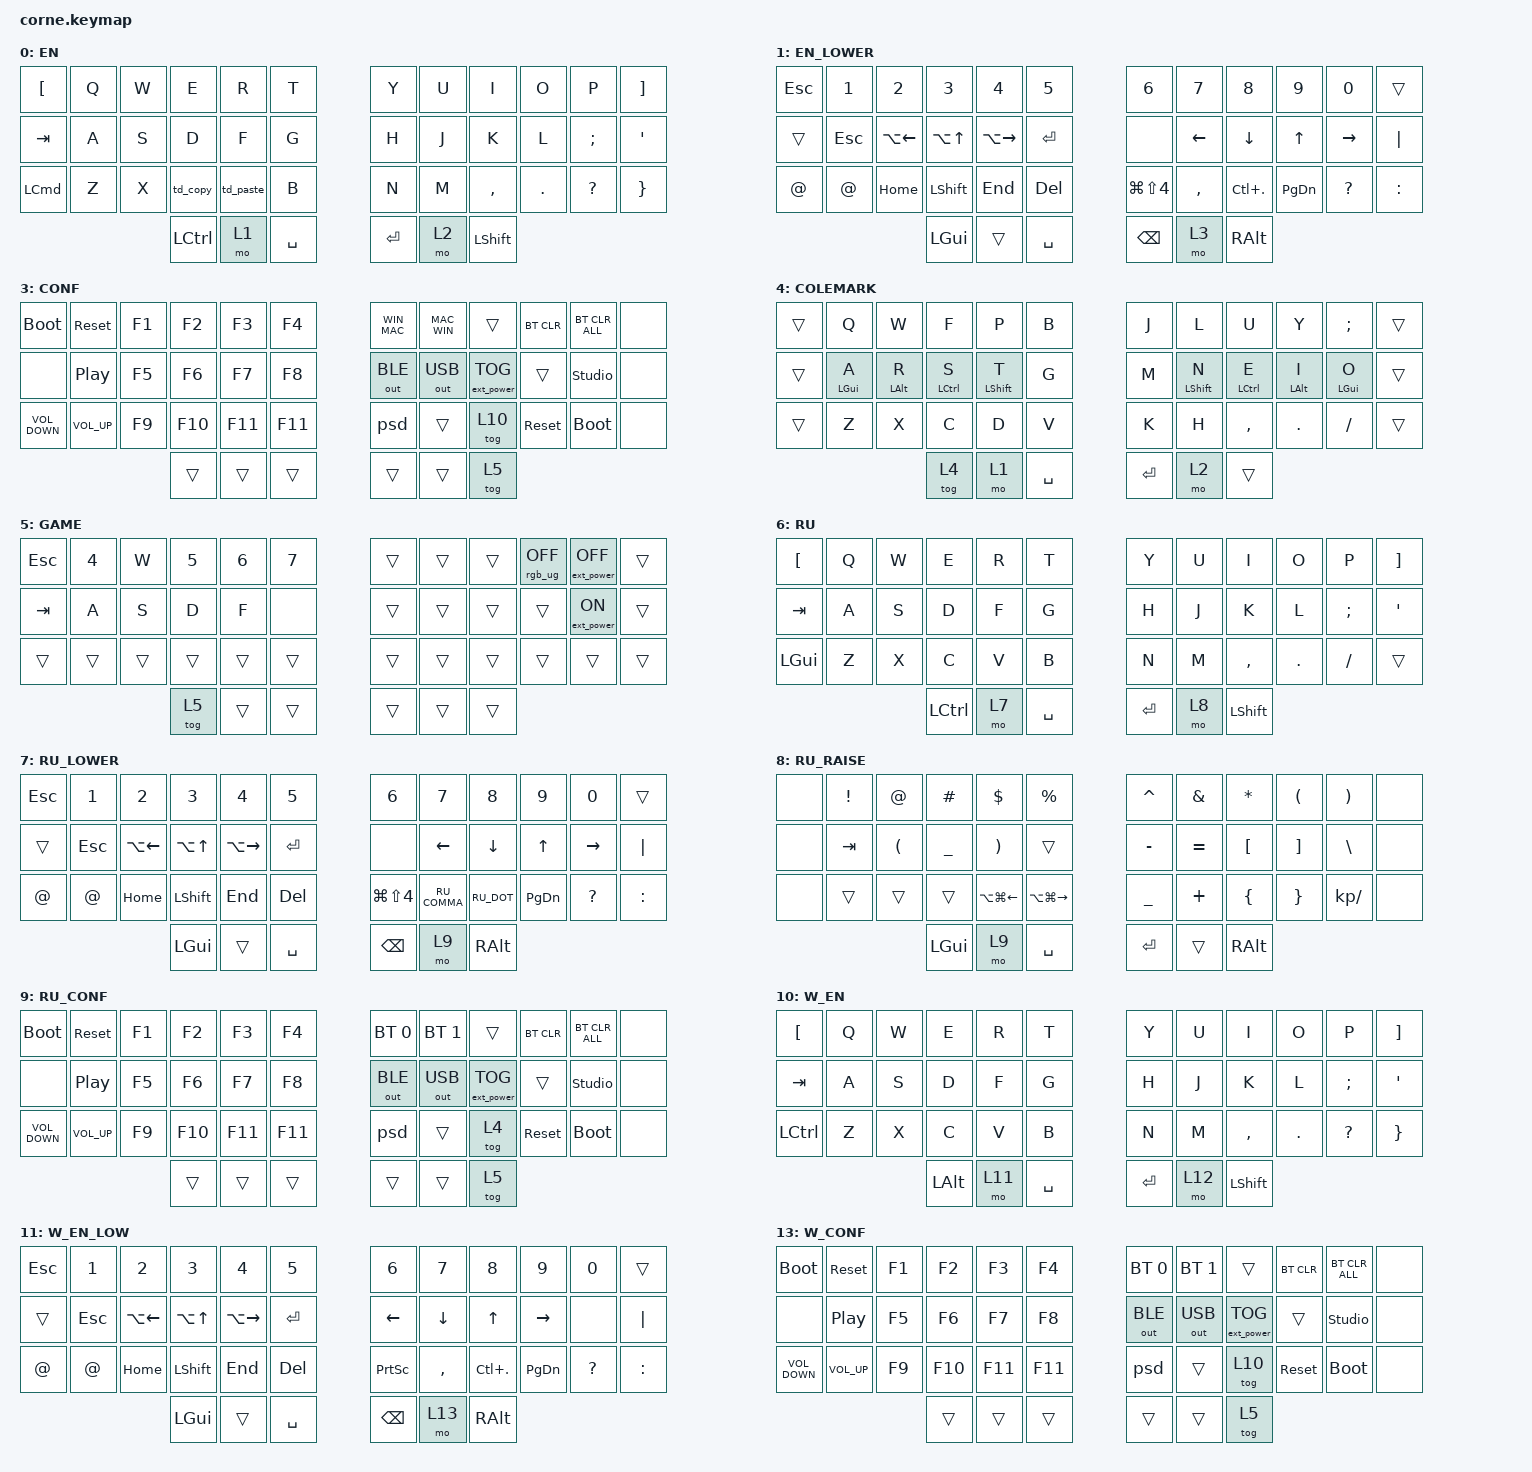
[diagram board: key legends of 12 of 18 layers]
/*
 * Copyright (c) 2020 The ZMK Contributors
 *
 * SPDX-License-Identifier: MIT
 */

#include <behaviors.dtsi>
#include <dt-bindings/zmk/bt.h>
#include <dt-bindings/zmk/ext_power.h>
#include <dt-bindings/zmk/keys.h>
#include <dt-bindings/zmk/outputs.h>
#include <dt-bindings/zmk/rgb.h>
#include "keys_ru.h"

&mt {
    tapping-term-ms = <200>;
    quick-tap-ms = <200>;
    require-prior-idle-ms = <125>;
    flavor = "tap-preferred";
};

// Переопределяем параметры дисплея ST7789
&st7789 {
    width = <240>;      // новая ширина (было 240, оставляем или меняем)
    height = <284>;     // меняем высоту, например, на 321 пикселей
    x-offset = <0>;     // смещение по X (было 0)
    y-offset = <0>;    // новое вертикальное смещение (было 20)
};

/ {
    macros {
        psd: new_macro {
            compatible = "zmk,behavior-macro";
            #binding-cells = <0>;
            bindings = <&kp LS(E) &kp C &kp N &kp F &kp N &kp Y &kp T &kp R &kp N5 &kp LS(A) &kp B &kp D &kp F &kp N5 &kp D &kp B &kp C &kp N1 &kp EXCL &kp EXCL &kp EXCL>;
            label = "NEW_MACRO";
        };

        to_ru: to_ru {
            compatible = "zmk,behavior-macro";
            #binding-cells = <0>;
            bindings = <&kp LS(LC(N2))>;
            label = "TO_RU";
        };

        to_en: to_en {
            compatible = "zmk,behavior-macro";
            #binding-cells = <0>;
            bindings = <&kp LS(LC(N1))>;
            label = "TO_EN";
        };

        layer_en: layer_en {
            compatible = "zmk,behavior-macro";
            #binding-cells = <0>;
            bindings = <&to 0 &to_en>;
            label = "LAYER_EN";
        };

        layer_ru: layer_ru {
            compatible = "zmk,behavior-macro";
            #binding-cells = <0>;
            bindings = <&to 6 &to_ru>;
            label = "LAYER_RU";
        };

        en: en {
            compatible = "zmk,behavior-macro-one-param";
            #binding-cells = <1>;
            bindings =
                <&to_en &macro_param_1to1 &kp MACRO_PLACEHOLDER>,
                <&macro_wait_time 10>,
                <&to_ru>,
                <&macro_wait_time 10>;

            label = "EN";
        };

        w_to_en: w_to_en {
            compatible = "zmk,behavior-macro";
            #binding-cells = <0>;
            bindings = <&to 10 &to_en>;
            label = "W_TO_EN";
        };

        w_to_ru: w_to_ru {
            compatible = "zmk,behavior-macro";
            #binding-cells = <0>;
            bindings = <&to 14 &to_ru>;
            label = "W_TO_RU";
        };

        MAC_WIN: MAC {
            compatible = "zmk,behavior-macro";
            #binding-cells = <0>;
            bindings = <&bt BT_SEL 0 &to 0>;
            label = "MAC";
        };

        WIN_MAC: WIN {
            compatible = "zmk,behavior-macro";
            #binding-cells = <0>;
            bindings = <&bt BT_SEL 1 &to 10>;
            label = "WIN";
        };
    };

    combos {
        compatible = "zmk,combos";

        esc {
            bindings = <&kp ESC>;
            key-positions = <0 1>;
            layers = <0>;
            timeout-ms = <40>;
        };

        tab {
            bindings = <&kp TAB>;
            key-positions = <12 13>;
            layers = <0>;
            timeout-ms = <40>;
        };

        RU_ENG {
            bindings = <&w_to_en>;
            key-positions = <4 3>;
            layers = <6 14>;
            require-prior-idle-ms = <200>;
        };

        TO_EN {
            bindings = <&w_to_ru>;
            key-positions = <3 4>;
            layers = <0 10>;
            require-prior-idle-ms = <200>;
        };

        ALT {
            bindings = <&kp LEFT_ALT>;
            key-positions = <28 29>;
            layers = <0 6>;
        };

        COPYW {
            bindings = <&kp LG(C)>;
            key-positions = <27 26>;
            timeout-ms = <300>;
            layers = <0 6>;
        };

        PASTE {
            bindings = <&kp LG(V)>;
            key-positions = <28 27>;
            timeout-ms = <300>;
            layers = <0 6>;
        };

        VIMESC {
            bindings = <&kp ESC>;
            key-positions = <4 5>;
            timeout-ms = <0>;
            layers = <0 10>;
            require-prior-idle-ms = <200>;
        };
    };

    behaviors {
        td_copy: td_copy {
            compatible = "zmk,behavior-tap-dance";
            label = "TD_COPY";
            #binding-cells = <0>;
            bindings = <&kp C>, <&kp LG(C)>;

            tapping-term-ms = <200>;
        };

        td_paste: td_paste {
            compatible = "zmk,behavior-tap-dance";
            label = "TD_PASTE";
            #binding-cells = <0>;
            bindings = <&kp V>, <&kp LG(V)>;

            tapping-term-ms = <200>;
        };

        mbq: mbq {
            compatible = "zmk,behavior-hold-tap";
            label = "MBQ";
            bindings = <&kp>, <&kp>;

            #binding-cells = <2>;
            tapping-term-ms = <250>;
            flavor = "tap-preferred";
        };
    };

    keymap {
        compatible = "zmk,keymap";

        EN {
            // -----------------------------------------------------------------------------------------
            // |  TAB |  Q  |  W  |  E  |  R  |  T  |   |  Y  |  U   |  I  |  O  |  P  | BSPC |
            // | CTRL |  A  |  S  |  D  |  F  |  G  |   |  H  |  J   |  K  |  L  |  ;  |  '   |
            // | SHFT |  Z  |  X  |  C  |  V  |  B  |   |  N  |  M   |  ,  |  .  |  /  | ESC  |
            //                    | GUI | LWR | SPC |   | ENT | RSE  | ALT |

            bindings = <
&kp LEFT_BRACKET  &kp Q  &kp W  &kp E      &kp R      &kp T        &kp Y    &kp U  &kp I           &kp O    &kp P          &kp RIGHT_BRACKET
&kp TAB           &kp A  &kp S  &kp D      &kp F      &kp G        &kp H    &kp J  &kp K           &kp L    &kp SEMICOLON  &kp SINGLE_QUOTE
&kp LCMD          &kp Z  &kp X  &td_copy   &td_paste  &kp B        &kp N    &kp M  &kp COMMA       &kp DOT  &kp QUESTION   &kp RIGHT_BRACE
                                &kp LCTRL  &mo 1      &kp SPACE    &kp RET  &mo 2  &kp LEFT_SHIFT
            >;

            label = "EN";
        };

        lower_layer_en {
            // -----------------------------------------------------------------------------------------
            // |  TAB |  1  |  2  |  3  |  4  |  5  |   |  6  |  7  |  8  |  9  |  0  | BSPC |
            // | BTCLR| BT1 | BT2 | BT3 | BT4 | BT5 |   | LFT | DWN |  UP | RGT |     |      |
            // | SHFT |     |     |     |     |     |   |     |     |     |     |     |      |
            //                    | GUI |     | SPC |   | ENT |     | ALT |

            bindings = <
&kp ESC  &kp N1       &kp N2        &kp N3          &kp N4         &kp N5       &kp N6                &kp N7     &kp N8          &kp N9         &kp N0           &trans
&trans   &kp ESC      &kp LA(LEFT)  &kp LA(UP)      &kp LA(RIGHT)  &kp ENTER    &none                 &kp LEFT   &kp DOWN_ARROW  &kp UP_ARROW   &kp RIGHT_ARROW  &kp PIPE
&kp AT   &kp AT_SIGN  &kp HOME      &kp LEFT_SHIFT  &kp END        &kp DEL      &kp LG(LS(NUMBER_4))  &kp COMMA  &kp LC(DOT)     &kp PAGE_DOWN  &kp QUESTION     &kp COLON
                                    &kp LGUI        &trans         &kp SPACE    &kp BACKSPACE         &mo 3      &kp RALT
            >;

            label = "EN_LOWER";
        };

        raise_layer_en {
            // -----------------------------------------------------------------------------------------
            // |  TAB |  !  |  @  |  #  |  $  |  %  |   |  ^  |  &  |  *  |  (  |  )  | BSPC |
            // | CTRL |     |     |     |     |     |   |  -  |  =  |  [  |  ]  |  \  |  `   |
            // | SHFT |     |     |     |     |     |   |  _  |  +  |  {  |  }  | "|" |  ~   |
            //                    | GUI |     | SPC |   | ENT |     | ALT |

            bindings = <
&none  &kp EXCL  &kp AT                &kp HASH        &kp DLLR                &kp PRCNT                  &kp CARET  &kp AMPS   &kp ASTRK  &kp LPAR  &kp RPAR      &none
&none  &kp TAB   &kp LEFT_PARENTHESIS  &kp UNDERSCORE  &kp RIGHT_PARENTHESIS   &kp LS(LA(LG(L)))          &kp MINUS  &kp EQUAL  &kp LBKT   &kp RBKT  &kp BSLH      &none
&none  &trans    &trans                &trans          &kp LA(LG(LEFT_ARROW))  &kp LA(LG(RIGHT_ARROW))    &kp UNDER  &kp PLUS   &kp LBRC   &kp RBRC  &kp KP_SLASH  &none
                                       &kp LGUI        &mo 3                   &kp SPACE                  &kp RET    &trans     &kp RALT
            >;

            label = "EN_RAISE";
        };

        conf {
            bindings = <
&bootloader        &sys_reset        &kp F1  &kp F2   &kp F3   &kp F4     &WIN_MAC      &MAC_WIN      &trans             &bt BT_CLR  &bt BT_CLR_ALL  &none
&none              &kp C_PLAY_PAUSE  &kp F5  &kp F6   &kp F7   &kp F8     &out OUT_BLE  &out OUT_USB  &ext_power EP_TOG  &trans      &studio_unlock  &none
&kp C_VOLUME_DOWN  &kp C_VOLUME_UP   &kp F9  &kp F10  &kp F11  &kp F11    &psd          &trans        &tog 10            &sys_reset  &bootloader     &none
                                             &trans   &trans   &trans     &trans        &trans        &tog 5
            >;

            label = "CONF";
        };

        colemark {
            bindings = <
&trans  &kp Q           &kp W           &kp F        &kp P             &kp B        &kp J      &kp L             &kp U        &kp Y           &kp SEMI        &trans
&trans  &mt LEFT_GUI A  &mt LEFT_ALT R  &mt LCTRL S  &mt LEFT_SHIFT T  &kp G        &kp M      &mt LEFT_SHIFT N  &mt LCTRL E  &mt LEFT_ALT I  &mt LEFT_GUI O  &trans
&trans  &kp Z           &kp X           &kp C        &kp D             &kp V        &kp K      &kp H             &kp COMMA    &kp DOT         &kp FSLH        &trans
                                        &tog 4       &mo 1             &kp SPACE    &kp ENTER  &mo 2             &trans
            >;

            label = "COLEMARK";
        };

        system {
            bindings = <
&kp ESCAPE  &kp NUMBER_4  &kp W   &kp N5  &kp NUMBER_6  &kp N7    &trans  &trans  &trans  &rgb_ug RGB_OFF  &ext_power EP_OFF  &trans
&kp TAB     &kp A         &kp S   &kp D   &kp F         &none     &trans  &trans  &trans  &trans           &ext_power EP_ON   &trans
&trans      &trans        &trans  &trans  &trans        &trans    &trans  &trans  &trans  &trans           &trans             &trans
                                  &tog 5  &trans        &trans    &trans  &trans  &trans
            >;

            label = "GAME";
        };

        RU {
            bindings = <
&kp LBKT  &kp Q  &kp W  &kp E      &kp R  &kp T        &kp Y      &kp U  &kp I      &kp O    &kp P     &kp RBKT
&kp TAB   &kp A  &kp S  &kp D      &kp F  &kp G        &kp H      &kp J  &kp K      &kp L    &kp SEMI  &kp APOS
&kp LGUI  &kp Z  &kp X  &kp C      &kp V  &kp B        &kp N      &kp M  &kp COMMA  &kp DOT  &kp FSLH  &trans
                        &kp LCTRL  &mo 7  &kp SPACE    &kp ENTER  &mo 8  &kp LSHFT
            >;

            label = "RU";
        };

        lower_layer_ru {
            bindings = <
&kp ESC  &kp N1       &kp N2        &kp N3          &kp N4         &kp N5       &kp N6                &kp N7        &kp N8          &kp N9         &kp N0           &trans
&trans   &kp ESC      &kp LA(LEFT)  &kp LA(UP)      &kp LA(RIGHT)  &kp ENTER    &none                 &kp LEFT      &kp DOWN_ARROW  &kp UP_ARROW   &kp RIGHT_ARROW  &kp PIPE
&kp AT   &kp AT_SIGN  &kp HOME      &kp LEFT_SHIFT  &kp END        &kp DEL      &kp LG(LS(NUMBER_4))  &kp RU_COMMA  &kp RU_DOT      &kp PAGE_DOWN  &kp QUESTION     &kp COLON
                                    &kp LGUI        &trans         &kp SPACE    &kp BACKSPACE         &mo 9         &kp RALT
            >;

            label = "RU_LOWER";
        };

        raise_layer_ru {
            bindings = <
&none  &kp EXCL  &kp AT                &kp HASH        &kp DLLR                &kp PRCNT                  &kp CARET  &kp AMPS   &kp ASTRK  &kp LPAR  &kp RPAR      &none
&none  &kp TAB   &kp LEFT_PARENTHESIS  &kp UNDERSCORE  &kp RIGHT_PARENTHESIS   &trans                     &kp MINUS  &kp EQUAL  &kp LBKT   &kp RBKT  &kp BSLH      &none
&none  &trans    &trans                &trans          &kp LA(LG(LEFT_ARROW))  &kp LA(LG(RIGHT_ARROW))    &kp UNDER  &kp PLUS   &kp LBRC   &kp RBRC  &kp KP_SLASH  &none
                                       &kp LGUI        &mo 9                   &kp SPACE                  &kp RET    &trans     &kp RALT
            >;

            label = "RU_RAISE";
        };

        RU_CONF {
            bindings = <
&bootloader        &sys_reset        &kp F1  &kp F2   &kp F3   &kp F4     &bt BT_SEL 0  &bt BT_SEL 1  &trans             &bt BT_CLR  &bt BT_CLR_ALL  &none
&none              &kp C_PLAY_PAUSE  &kp F5  &kp F6   &kp F7   &kp F8     &out OUT_BLE  &out OUT_USB  &ext_power EP_TOG  &trans      &studio_unlock  &none
&kp C_VOLUME_DOWN  &kp C_VOLUME_UP   &kp F9  &kp F10  &kp F11  &kp F11    &psd          &trans        &tog 4             &sys_reset  &bootloader     &none
                                             &trans   &trans   &trans     &trans        &trans        &tog 5
            >;

            label = "RU_CONF";
        };

        W_EN {
            label = "W_EN";
            bindings = <
&kp LEFT_BRACKET  &kp Q  &kp W  &kp E         &kp R   &kp T        &kp Y    &kp U   &kp I           &kp O    &kp P          &kp RIGHT_BRACKET
&kp TAB           &kp A  &kp S  &kp D         &kp F   &kp G        &kp H    &kp J   &kp K           &kp L    &kp SEMICOLON  &kp SINGLE_QUOTE
&kp LCTRL         &kp Z  &kp X  &kp C         &kp V   &kp B        &kp N    &kp M   &kp COMMA       &kp DOT  &kp QUESTION   &kp RIGHT_BRACE
                                &kp LEFT_ALT  &mo 11  &kp SPACE    &kp RET  &mo 12  &kp LEFT_SHIFT
            >;
        };

        W_EN_LOWER {
            label = "W_EN_LOW";
            bindings = <
&kp ESC  &kp N1       &kp N2        &kp N3          &kp N4         &kp N5       &kp N6         &kp N7     &kp N8        &kp N9           &kp N0        &trans
&trans   &kp ESC      &kp LA(LEFT)  &kp LA(UP)      &kp LA(RIGHT)  &kp ENTER    &kp LEFT       &kp DOWN   &kp UP_ARROW  &kp RIGHT_ARROW  &none         &kp PIPE
&kp AT   &kp AT_SIGN  &kp HOME      &kp LEFT_SHIFT  &kp END        &kp DEL      &kp PSCRN      &kp COMMA  &kp LC(DOT)   &kp PAGE_DOWN    &kp QUESTION  &kp COLON
                                    &kp LGUI        &trans         &kp SPACE    &kp BACKSPACE  &mo 13     &kp RALT
            >;
        };

        W_EN_RAISE {
            label = "W_EN_RAISE";
            bindings = <
&none  &kp EXCL  &kp AT                &kp HASH        &kp DLLR                &kp PRCNT                  &kp CARET  &kp AMPS   &kp ASTRK  &kp LPAR  &kp RPAR      &none
&none  &kp TAB   &kp LEFT_PARENTHESIS  &kp UNDERSCORE  &kp RIGHT_PARENTHESIS   &kp LS(LA(LG(L)))          &kp MINUS  &kp EQUAL  &kp LBKT   &kp RBKT  &kp BSLH      &none
&none  &trans    &trans                &trans          &kp LA(LG(LEFT_ARROW))  &kp LA(LG(RIGHT_ARROW))    &kp UNDER  &kp PLUS   &kp LBRC   &kp RBRC  &kp KP_SLASH  &none
                                       &kp LGUI        &mo 13                  &kp SPACE                  &kp RET    &trans     &kp RALT
            >;
        };

        W_CONF {
            label = "W_CONF";
            bindings = <
&bootloader        &sys_reset        &kp F1  &kp F2   &kp F3   &kp F4     &bt BT_SEL 0  &bt BT_SEL 1  &trans             &bt BT_CLR  &bt BT_CLR_ALL  &none
&none              &kp C_PLAY_PAUSE  &kp F5  &kp F6   &kp F7   &kp F8     &out OUT_BLE  &out OUT_USB  &ext_power EP_TOG  &trans      &studio_unlock  &none
&kp C_VOLUME_DOWN  &kp C_VOLUME_UP   &kp F9  &kp F10  &kp F11  &kp F11    &psd          &trans        &tog 10            &sys_reset  &bootloader     &none
                                             &trans   &trans   &trans     &trans        &trans        &tog 5
            >;
        };

        W_RU {
            label = "W_RU";
            bindings = <
&kp LBKT   &kp Q  &kp W  &kp E         &kp R   &kp T        &kp Y      &kp U   &kp I      &kp O    &kp P     &kp RBKT
&kp TAB    &kp A  &kp S  &kp D         &kp F   &kp G        &kp H      &kp J   &kp K      &kp L    &kp SEMI  &kp APOS
&kp LCTRL  &kp Z  &kp X  &kp C         &kp V   &kp B        &kp N      &kp M   &kp COMMA  &kp DOT  &kp FSLH  &trans
                         &kp LEFT_ALT  &mo 15  &kp SPACE    &kp ENTER  &mo 16  &kp LSHFT
            >;
        };

        W_RU_LOWER {
            label = "W_RU_LOW";
            bindings = <
&kp ESC  &kp N1       &kp N2        &kp N3          &kp N4         &kp N5       &kp N6           &kp N7          &kp N8        &kp N9           &kp N0        &trans
&trans   &kp ESC      &kp LA(LEFT)  &kp LA(UP)      &kp LA(RIGHT)  &kp ENTER    &kp LEFT_ARROW   &kp DOWN_ARROW  &kp UP_ARROW  &kp RIGHT_ARROW  &kp ENTER     &kp PIPE
&kp AT   &kp AT_SIGN  &kp HOME      &kp LEFT_SHIFT  &kp END        &kp DEL      &kp PRINTSCREEN  &kp RU_COMMA    &kp RU_DOT    &kp PAGE_DOWN    &kp QUESTION  &kp COLON
                                    &kp LGUI        &trans         &kp SPACE    &kp BACKSPACE    &mo 17          &kp RALT
            >;
        };

        W_RU_RAISE {
            label = "W_RU_RAISE";
            bindings = <
&none  &kp EXCL  &kp AT                &kp HASH        &kp DLLR                &kp PRCNT                  &kp CARET  &kp AMPS   &kp ASTRK  &kp LPAR  &kp RPAR      &none
&none  &kp TAB   &kp LEFT_PARENTHESIS  &kp UNDERSCORE  &kp RIGHT_PARENTHESIS   &trans                     &kp MINUS  &kp EQUAL  &kp LBKT   &kp RBKT  &kp BSLH      &none
&none  &trans    &trans                &trans          &kp LA(LG(LEFT_ARROW))  &kp LA(LG(RIGHT_ARROW))    &kp UNDER  &kp PLUS   &kp LBRC   &kp RBRC  &kp KP_SLASH  &none
                                       &kp LGUI        &mo 17                  &kp SPACE                  &kp RET    &trans     &kp RALT
            >;
        };

        W_RU_CONF {
            label = "W_RU_CONF";
            bindings = <
&bootloader        &sys_reset        &kp F1  &kp F2   &kp F3   &kp F4     &bt BT_SEL 0  &bt BT_SEL 1  &trans             &bt BT_CLR  &bt BT_CLR_ALL  &none
&none              &kp C_PLAY_PAUSE  &kp F5  &kp F6   &kp F7   &kp F8     &out OUT_BLE  &out OUT_USB  &ext_power EP_TOG  &trans      &studio_unlock  &none
&kp C_VOLUME_DOWN  &kp C_VOLUME_UP   &kp F9  &kp F10  &kp F11  &kp F11    &psd          &trans        &tog 4             &sys_reset  &bootloader     &none
                                             &trans   &trans   &trans     &trans        &trans        &tog 5
            >;
        };
    };
};
